# BAT32G135 register map
Vendor: CMS; Series: BAT32G135; File version: 1.2
CPU: CM0+ r0p1, little endian, no MPU, no FPU, VTOR, 2 interrupt priority bits
Registers are 8-bit, read-write, reset 0x0 unless marked. A register's access mark holds for its fields unless they carry their own. Offsets are from the block's base; [hi:lo] are bit positions; {n}, {i} and the like mark numbered series; 'fields as' and 'values as' point back to an identical list.

## PGA — Programmable Gain Amplifier
Base 0x40043840; alternate view of CMP
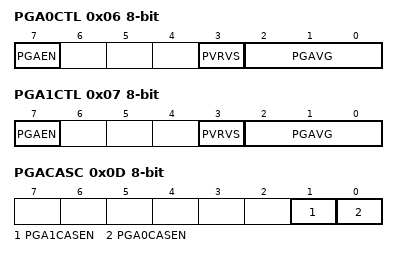
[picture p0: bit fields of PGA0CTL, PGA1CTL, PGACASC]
0x06 PGA0CTL (reset mask 0x8B) — PGA 0 control register
  [7] PGAEN — Programmable gain amplifier operation control
  [3] PVRVS — GND selection of feedback resistance of the programmable gain amplifier
  [2:0] PGAVG — Programmable gain amplifier amplification factor selection
0x07 PGA1CTL (reset mask 0x8B) — PGA 1 control register
  fields as PGA0CTL
0x0C PGAPRCR — PGA protect register
0x0D PGACASC — PGA cascade enable register
  [1] PGA1CASEN — PGA1 cascade connect enable
    0=DISABLE (PGA1 cascade connect disable); 1=ENABLE (PGA1 cascade connect enable)
  [0] PGA0CASEN — PGA0 cascade connect enable
    0=DISABLE (PGA0 cascade connect disable); 1=ENABLE (PGA0 cascade connect enable)

## SCI0 — Serial Communication Interface 0 with UART, SPI and simplified I2C supported
Base 0x40041100
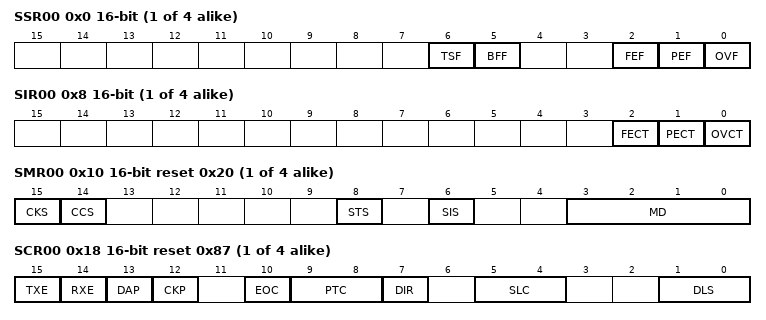
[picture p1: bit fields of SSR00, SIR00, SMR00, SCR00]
{0x0+2i} SSR{i:02} 16-bit ro (i=0..3) — Serial status register mn
  [6] TSF — Communication status indication flag of channel n
  [5] BFF — Buffer register status indication flag of channel n
  [2] FEF — Framing error detection flag of channel n
  [1] PEF — Parity error detection flag of channel n
  [0] OVF — Overrun error detection flag of channel n
{0x8+2i} SIR{i:02} 16-bit (i=0..3) — Serial flag clear trigger register mn
  [2] FECT — Clear trigger of framing error flag of channel n
  [1] PECT — Clear trigger of parity error flag of channel n
  [0] OVCT — Clear trigger of overrun error flag of channel n
{0x10+2i} SMR{i:02} 16-bit reset 0x20 (reset mask 0xC147) (i=0..3) — Serial mode register mn
  [15] CKS — Selection of operation clock (fMCK) of channel n
  [14] CCS — Selection of transfer clock (fTCLK) of channel n
  [8] STS — Selection of start trigger source
  [6] SIS — Controls inversion of level of receive data of channel n in UART mode
  [3:0] MD — Setting of operation mode of channel n
{0x18+2i} SCR{i:02} 16-bit reset 0x87 (i=0..3) — Serial communication operation setting register mn
  [15] TXE — Transmission enable
  [14] RXE — Reception enable
  [13] DAP — Selection of data phase in SPI mode
  [12] CKP — Selection of clock phase in SPI mode
  [10] EOC — Mask control of error interrupt signal (INTSREx (x = 0 to 2))
  [9:8] PTC — Setting of parity bit in UART mode
  [7] DIR — Selection of data transfer sequence in SPI and UART modes
  [5:4] SLC — Setting of stop bit in UART mode
  [1:0] DLS — Setting of data length in SPI and UART modes
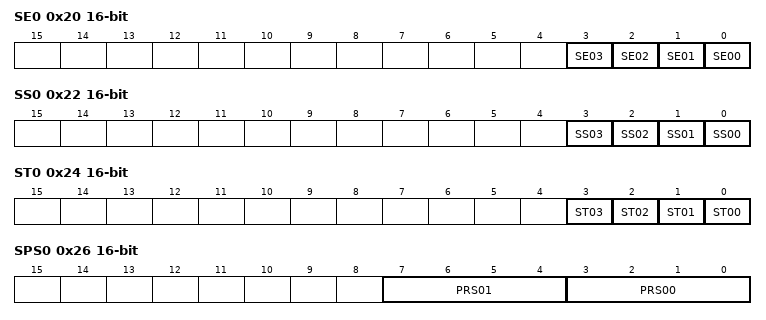
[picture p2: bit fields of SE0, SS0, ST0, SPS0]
0x20 SE0 16-bit ro — Serial channel enable status register m
  [n] SE{n:02} (n=0..3) — Indication of operation enable/stop status of channel {n}
0x22 SS0 16-bit — Serial channel start register 0
  [n] SS{n:02} (n=0..3) — Operation start trigger of channel {n}
0x24 ST0 16-bit — Serial channel stop register 0
  [n] ST{n:02} (n=0..3) — Operation stop trigger of channel {n}
0x26 SPS0 16-bit — Serial clock select register 0
  [7:4] PRS01 — Prescaler 1
  [3:0] PRS00 — Prescaler 0
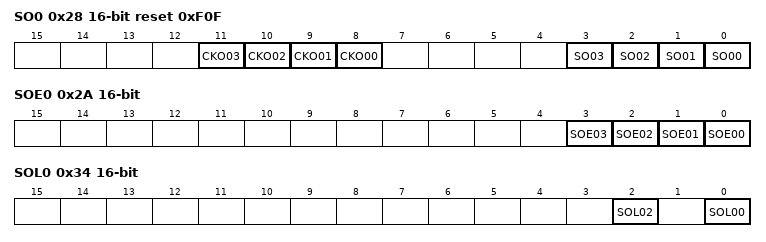
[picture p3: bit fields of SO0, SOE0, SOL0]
0x28 SO0 16-bit reset 0xF0F — Serial output register 0
  [n+8] CKO{n:02} (n=0..3) — Serial clock output of channel {n}
  [n] SO{n:02} (n=0..3) — Serial data output of channel {n}
0x2A SOE0 16-bit — Serial output enable register 0
  [n] SOE{n:02} (n=0..3) — Serial output enable of channel {n}
0x34 SOL0 16-bit — Serial output level register 0
  [2] SOL02 — Selects inversion of the level of the transmit data of channel n in UART mode
  [0] SOL00 — Selects inversion of the level of the transmit data of channel n in UART mode
{0x210+2i} SDR0{i} (i=0..1) 16-bit — Serial data register 0{i}
0x210 SIO00 (alternate view of SDR00) — SPI data register
0x210 TXD0 (alternate view of SDR00) — UART transmit data register
0x212 SIO01 (alternate view of SDR01) — SPI data register
0x212 RXD0 (alternate view of SDR01) — UART receive data register
{0x240+2i} SDR0{i} (i=2..3) 16-bit — Serial data register 0{i}
0x244 SIO10 (alternate view of SDR02) — SPI data register
0x244 TXD1 (alternate view of SDR02) — UART transmit data register
0x246 SIO11 (alternate view of SDR03) — SPI data register
0x246 RXD1 (alternate view of SDR03) — UART receive data register
